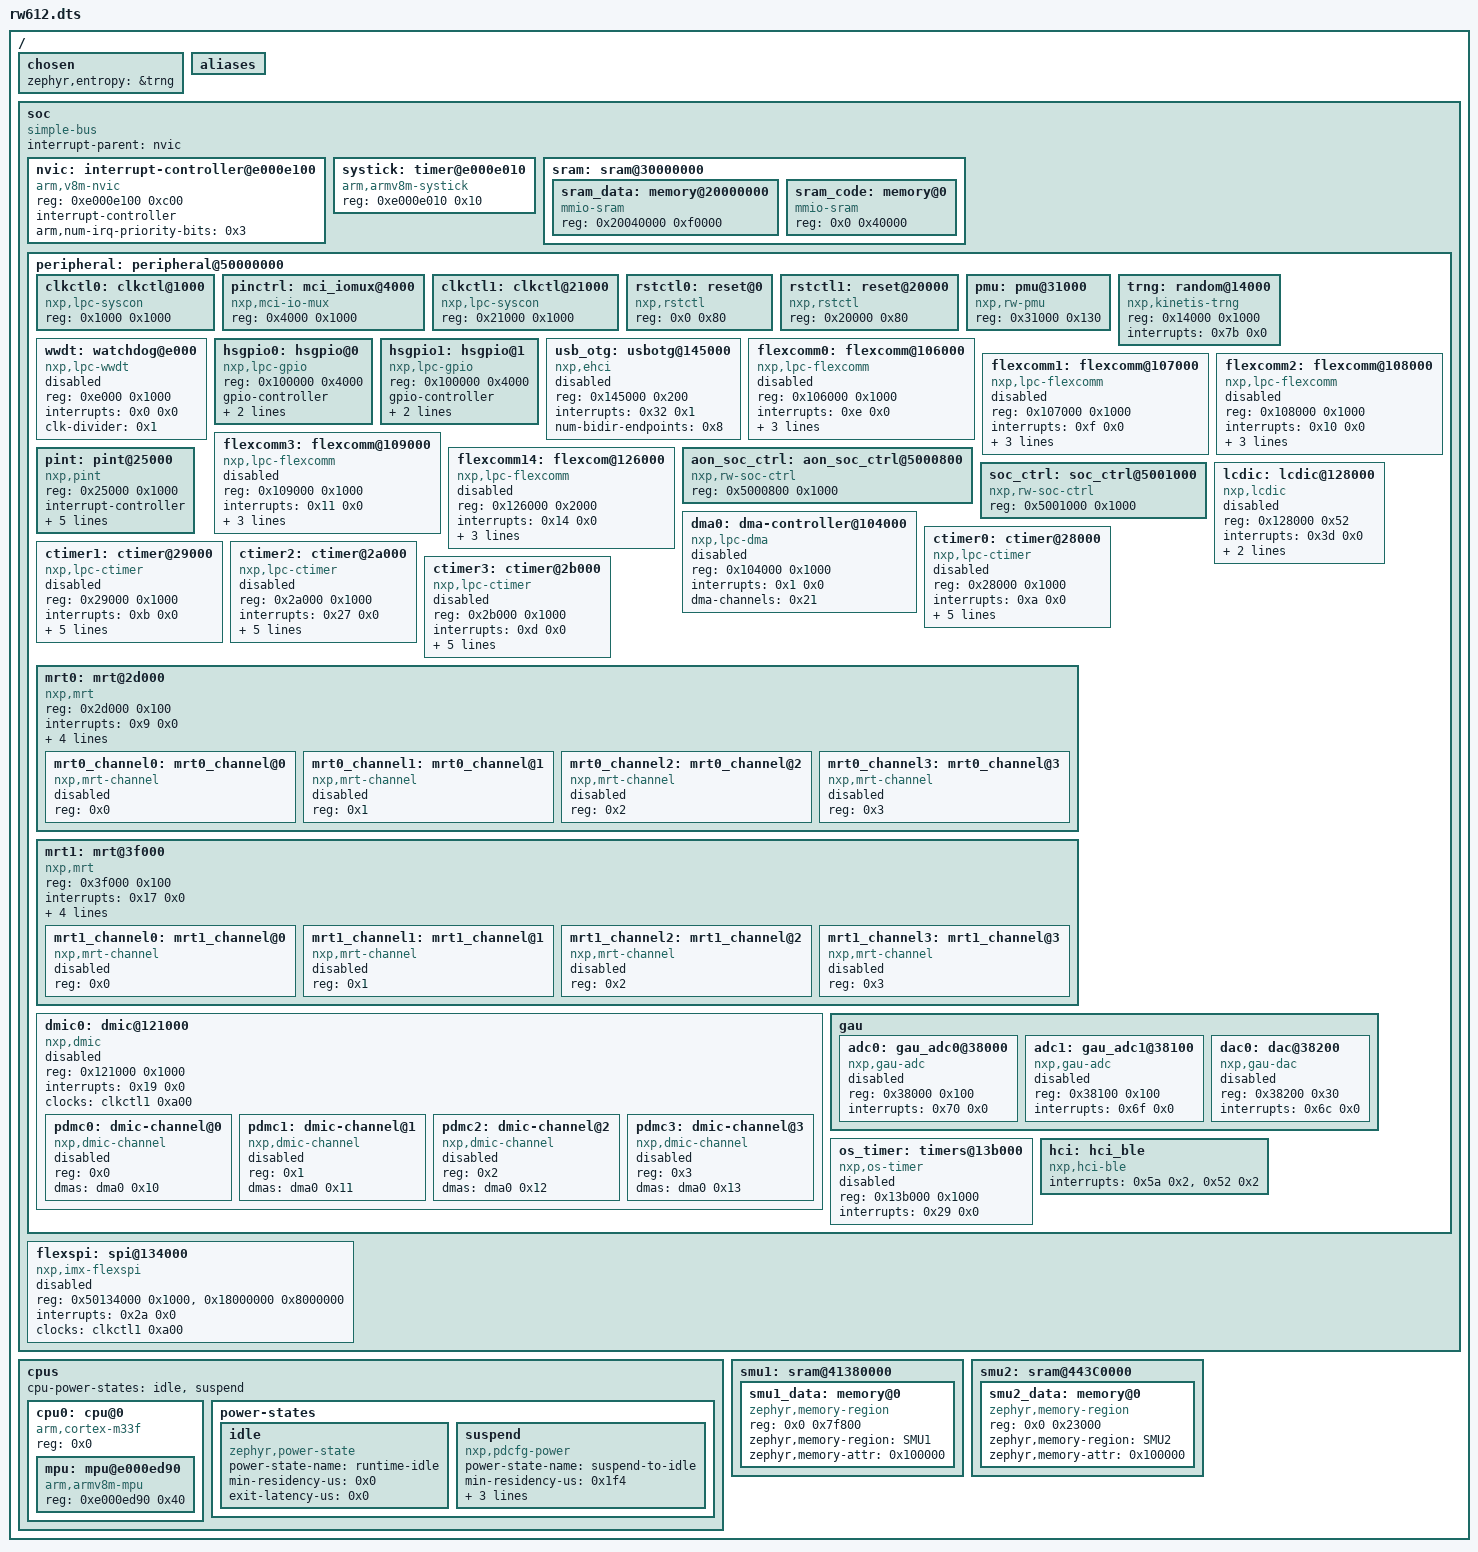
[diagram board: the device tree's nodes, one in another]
/dts-v1/;

/ {
	#address-cells = < 0x1 >;
	#size-cells = < 0x1 >;
	chosen {
		zephyr,entropy = &trng;
	};
	aliases {
	};
	soc {
		#address-cells = < 0x1 >;
		#size-cells = < 0x1 >;
		compatible = "simple-bus";
		interrupt-parent = < &nvic >;
		ranges;
		nvic: interrupt-controller@e000e100 {
			#address-cells = < 0x1 >;
			compatible = "arm,v8m-nvic";
			reg = < 0xe000e100 0xc00 >;
			interrupt-controller;
			#interrupt-cells = < 0x2 >;
			arm,num-irq-priority-bits = < 0x3 >;
			phandle = < 0x1 >;
		};
		systick: timer@e000e010 {
			compatible = "arm,armv8m-systick";
			reg = < 0xe000e010 0x10 >;
		};
		sram: sram@30000000 {
			ranges = < 0x20000000 0x30000000 0x130000 0x0 0x10000000 0x130000 >;
			#address-cells = < 0x1 >;
			#size-cells = < 0x1 >;
			sram_data: memory@20000000 {
				compatible = "mmio-sram";
				reg = < 0x20040000 0xf0000 >;
			};
			sram_code: memory@0 {
				compatible = "mmio-sram";
				reg = < 0x0 0x40000 >;
			};
		};
		peripheral: peripheral@50000000 {
			ranges = < 0x0 0x50000000 0x10000000 >;
			#address-cells = < 0x1 >;
			#size-cells = < 0x1 >;
			clkctl0: clkctl@1000 {
				compatible = "nxp,lpc-syscon";
				reg = < 0x1000 0x1000 >;
				#clock-cells = < 0x1 >;
			};
			pinctrl: mci_iomux@4000 {
				compatible = "nxp,mci-io-mux";
				reg = < 0x4000 0x1000 >;
				status = "okay";
			};
			clkctl1: clkctl@21000 {
				compatible = "nxp,lpc-syscon";
				reg = < 0x21000 0x1000 >;
				#clock-cells = < 0x1 >;
				phandle = < 0x2 >;
			};
			rstctl0: reset@0 {
				compatible = "nxp,rstctl";
				reg = < 0x0 0x80 >;
				#reset-cells = < 0x1 >;
				phandle = < 0x5 >;
			};
			rstctl1: reset@20000 {
				compatible = "nxp,rstctl";
				reg = < 0x20000 0x80 >;
				#reset-cells = < 0x1 >;
				phandle = < 0x3 >;
			};
			pmu: pmu@31000 {
				reg = < 0x31000 0x130 >;
				compatible = "nxp,rw-pmu";
			};
			trng: random@14000 {
				compatible = "nxp,kinetis-trng";
				reg = < 0x14000 0x1000 >;
				status = "okay";
				interrupts = < 0x7b 0x0 >;
			};
			wwdt: watchdog@e000 {
				compatible = "nxp,lpc-wwdt";
				reg = < 0xe000 0x1000 >;
				interrupts = < 0x0 0x0 >;
				status = "disabled";
				clk-divider = < 0x1 >;
			};
			hsgpio0: hsgpio@0 {
				compatible = "nxp,lpc-gpio";
				reg = < 0x100000 0x4000 >;
				gpio-controller;
				#gpio-cells = < 0x2 >;
				port = < 0x0 >;
				int-source = "pint";
			};
			hsgpio1: hsgpio@1 {
				compatible = "nxp,lpc-gpio";
				reg = < 0x100000 0x4000 >;
				gpio-controller;
				#gpio-cells = < 0x2 >;
				port = < 0x1 >;
				int-source = "pint";
			};
			usb_otg: usbotg@145000 {
				compatible = "nxp,ehci";
				reg = < 0x145000 0x200 >;
				interrupts = < 0x32 0x1 >;
				interrupt-names = "usb_otg";
				num-bidir-endpoints = < 0x8 >;
				status = "disabled";
			};
			flexcomm0: flexcomm@106000 {
				compatible = "nxp,lpc-flexcomm";
				reg = < 0x106000 0x1000 >;
				interrupts = < 0xe 0x0 >;
				clocks = < &clkctl1 0x100 >;
				resets = < &rstctl1 0x8 >;
				dmas = < &dma0 0x0 >, < &dma0 0x1 >;
				dma-names = "rx", "tx";
				status = "disabled";
			};
			flexcomm1: flexcomm@107000 {
				compatible = "nxp,lpc-flexcomm";
				reg = < 0x107000 0x1000 >;
				interrupts = < 0xf 0x0 >;
				clocks = < &clkctl1 0x101 >;
				resets = < &rstctl1 0x9 >;
				dmas = < &dma0 0x2 >, < &dma0 0x3 >;
				dma-names = "rx", "tx";
				status = "disabled";
			};
			flexcomm2: flexcomm@108000 {
				compatible = "nxp,lpc-flexcomm";
				reg = < 0x108000 0x1000 >;
				interrupts = < 0x10 0x0 >;
				clocks = < &clkctl1 0x102 >;
				resets = < &rstctl1 0xa >;
				dmas = < &dma0 0x4 >, < &dma0 0x5 >;
				dma-names = "rx", "tx";
				status = "disabled";
			};
			flexcomm3: flexcomm@109000 {
				compatible = "nxp,lpc-flexcomm";
				reg = < 0x109000 0x1000 >;
				interrupts = < 0x11 0x0 >;
				clocks = < &clkctl1 0x103 >;
				resets = < &rstctl1 0xb >;
				dmas = < &dma0 0x6 >, < &dma0 0x7 >;
				dma-names = "rx", "tx";
				status = "disabled";
			};
			flexcomm14: flexcom@126000 {
				compatible = "nxp,lpc-flexcomm";
				reg = < 0x126000 0x2000 >;
				interrupts = < 0x14 0x0 >;
				clocks = < &clkctl1 0x10e >;
				resets = < &rstctl1 0x16 >;
				dmas = < &dma0 0x1a >, < &dma0 0x1b >;
				dma-names = "rx", "tx";
				status = "disabled";
			};
			aon_soc_ctrl: aon_soc_ctrl@5000800 {
				compatible = "nxp,rw-soc-ctrl";
				reg = < 0x5000800 0x1000 >;
				status = "okay";
			};
			soc_ctrl: soc_ctrl@5001000 {
				compatible = "nxp,rw-soc-ctrl";
				reg = < 0x5001000 0x1000 >;
				status = "okay";
			};
			pint: pint@25000 {
				compatible = "nxp,pint";
				reg = < 0x25000 0x1000 >;
				interrupt-controller;
				#interrupt-cells = < 0x1 >;
				#address-cells = < 0x0 >;
				interrupts = < 0x4 0x2 >, < 0x5 0x2 >, < 0x6 0x2 >, < 0x7 0x2 >, < 0x23 0x2 >, < 0x24 0x2 >, < 0x25 0x2 >, < 0x26 0x2 >;
				num-lines = < 0x8 >;
				num-inputs = < 0x40 >;
			};
			dma0: dma-controller@104000 {
				compatible = "nxp,lpc-dma";
				reg = < 0x104000 0x1000 >;
				interrupts = < 0x1 0x0 >;
				status = "disabled";
				#dma-cells = < 0x1 >;
				dma-channels = < 0x21 >;
				phandle = < 0x4 >;
			};
			lcdic: lcdic@128000 {
				compatible = "nxp,lcdic";
				reg = < 0x128000 0x52 >;
				interrupts = < 0x3d 0x0 >;
				status = "disabled";
				#address-cells = < 0x1 >;
				#size-cells = < 0x0 >;
				clocks = < &clkctl1 0xe00 >;
				dmas = < &dma0 0x0 >;
			};
			ctimer0: ctimer@28000 {
				compatible = "nxp,lpc-ctimer";
				reg = < 0x28000 0x1000 >;
				interrupts = < 0xa 0x0 >;
				status = "disabled";
				clk-source = < 0x1 >;
				clocks = < &clkctl1 0x0 >;
				mode = < 0x0 >;
				input = < 0x0 >;
				prescale = < 0x0 >;
			};
			ctimer1: ctimer@29000 {
				compatible = "nxp,lpc-ctimer";
				reg = < 0x29000 0x1000 >;
				interrupts = < 0xb 0x0 >;
				status = "disabled";
				clk-source = < 0x1 >;
				clocks = < &clkctl1 0x1 >;
				mode = < 0x0 >;
				input = < 0x0 >;
				prescale = < 0x0 >;
			};
			ctimer2: ctimer@2a000 {
				compatible = "nxp,lpc-ctimer";
				reg = < 0x2a000 0x1000 >;
				interrupts = < 0x27 0x0 >;
				status = "disabled";
				clk-source = < 0x1 >;
				clocks = < &clkctl1 0x2 >;
				mode = < 0x0 >;
				input = < 0x0 >;
				prescale = < 0x0 >;
			};
			ctimer3: ctimer@2b000 {
				compatible = "nxp,lpc-ctimer";
				reg = < 0x2b000 0x1000 >;
				interrupts = < 0xd 0x0 >;
				status = "disabled";
				clk-source = < 0x1 >;
				clocks = < &clkctl1 0x3 >;
				mode = < 0x0 >;
				input = < 0x0 >;
				prescale = < 0x0 >;
			};
			mrt0: mrt@2d000 {
				compatible = "nxp,mrt";
				reg = < 0x2d000 0x100 >;
				interrupts = < 0x9 0x0 >;
				num-channels = < 0x4 >;
				num-bits = < 0x18 >;
				clocks = < &clkctl1 0xb00 >;
				resets = < &rstctl1 0x20008 >;
				#address-cells = < 0x1 >;
				#size-cells = < 0x0 >;
				mrt0_channel0: mrt0_channel@0 {
					compatible = "nxp,mrt-channel";
					reg = < 0x0 >;
					status = "disabled";
				};
				mrt0_channel1: mrt0_channel@1 {
					compatible = "nxp,mrt-channel";
					reg = < 0x1 >;
					status = "disabled";
				};
				mrt0_channel2: mrt0_channel@2 {
					compatible = "nxp,mrt-channel";
					reg = < 0x2 >;
					status = "disabled";
				};
				mrt0_channel3: mrt0_channel@3 {
					compatible = "nxp,mrt-channel";
					reg = < 0x3 >;
					status = "disabled";
				};
			};
			mrt1: mrt@3f000 {
				compatible = "nxp,mrt";
				reg = < 0x3f000 0x100 >;
				interrupts = < 0x17 0x0 >;
				num-channels = < 0x4 >;
				num-bits = < 0x18 >;
				clocks = < &clkctl1 0xb01 >;
				resets = < &rstctl0 0x2001a >;
				#address-cells = < 0x1 >;
				#size-cells = < 0x0 >;
				mrt1_channel0: mrt1_channel@0 {
					compatible = "nxp,mrt-channel";
					reg = < 0x0 >;
					status = "disabled";
				};
				mrt1_channel1: mrt1_channel@1 {
					compatible = "nxp,mrt-channel";
					reg = < 0x1 >;
					status = "disabled";
				};
				mrt1_channel2: mrt1_channel@2 {
					compatible = "nxp,mrt-channel";
					reg = < 0x2 >;
					status = "disabled";
				};
				mrt1_channel3: mrt1_channel@3 {
					compatible = "nxp,mrt-channel";
					reg = < 0x3 >;
					status = "disabled";
				};
			};
			dmic0: dmic@121000 {
				#address-cells = < 0x1 >;
				#size-cells = < 0x0 >;
				compatible = "nxp,dmic";
				reg = < 0x121000 0x1000 >;
				interrupts = < 0x19 0x0 >;
				status = "disabled";
				clocks = < &clkctl1 0xa00 >;
				pdmc0: dmic-channel@0 {
					reg = < 0x0 >;
					compatible = "nxp,dmic-channel";
					dmas = < &dma0 0x10 >;
					status = "disabled";
				};
				pdmc1: dmic-channel@1 {
					reg = < 0x1 >;
					compatible = "nxp,dmic-channel";
					dmas = < &dma0 0x11 >;
					status = "disabled";
				};
				pdmc2: dmic-channel@2 {
					reg = < 0x2 >;
					compatible = "nxp,dmic-channel";
					dmas = < &dma0 0x12 >;
					status = "disabled";
				};
				pdmc3: dmic-channel@3 {
					reg = < 0x3 >;
					compatible = "nxp,dmic-channel";
					dmas = < &dma0 0x13 >;
					status = "disabled";
				};
			};
			gau {
				ranges;
				#address-cells = < 0x1 >;
				#size-cells = < 0x1 >;
				adc0: gau_adc0@38000 {
					compatible = "nxp,gau-adc";
					reg = < 0x38000 0x100 >;
					interrupts = < 0x70 0x0 >;
					status = "disabled";
					#io-channel-cells = < 0x1 >;
				};
				adc1: gau_adc1@38100 {
					compatible = "nxp,gau-adc";
					reg = < 0x38100 0x100 >;
					interrupts = < 0x6f 0x0 >;
					status = "disabled";
					#io-channel-cells = < 0x1 >;
				};
				dac0: dac@38200 {
					compatible = "nxp,gau-dac";
					reg = < 0x38200 0x30 >;
					interrupts = < 0x6c 0x0 >;
					status = "disabled";
					#io-channel-cells = < 0x0 >;
				};
			};
			os_timer: timers@13b000 {
				compatible = "nxp,os-timer";
				reg = < 0x13b000 0x1000 >;
				interrupts = < 0x29 0x0 >;
				status = "disabled";
			};
			hci: hci_ble {
				compatible = "nxp,hci-ble";
				interrupts = < 0x5a 0x2 >, < 0x52 0x2 >;
				interrupt-names = "hci_int", "wakeup_int";
			};
		};
		flexspi: spi@134000 {
			reg = < 0x50134000 0x1000 >, < 0x18000000 0x8000000 >;
			compatible = "nxp,imx-flexspi";
			status = "disabled";
			interrupts = < 0x2a 0x0 >;
			#address-cells = < 0x1 >;
			#size-cells = < 0x0 >;
			clocks = < &clkctl1 0xa00 >;
		};
	};
	cpus {
		#address-cells = < 0x1 >;
		#size-cells = < 0x0 >;
		cpu-power-states = < &idle &suspend >;
		cpu0: cpu@0 {
			compatible = "arm,cortex-m33f";
			reg = < 0x0 >;
			#address-cells = < 0x1 >;
			#size-cells = < 0x1 >;
			mpu: mpu@e000ed90 {
				compatible = "arm,armv8m-mpu";
				reg = < 0xe000ed90 0x40 >;
			};
		};
		power-states {
			idle: idle {
				compatible = "zephyr,power-state";
				power-state-name = "runtime-idle";
				min-residency-us = < 0x0 >;
				exit-latency-us = < 0x0 >;
				phandle = < 0x6 >;
			};
			suspend: suspend {
				compatible = "nxp,pdcfg-power", "zephyr,power-state";
				power-state-name = "suspend-to-idle";
				min-residency-us = < 0x1f4 >;
				exit-latency-us = < 0x78 >;
				deep-sleep-config = < 0x180000 >, < 0x0 >, < 0x4 >, < 0x100 >, < 0x0 >;
				phandle = < 0x7 >;
			};
		};
	};
	smu1: sram@41380000 {
		ranges = < 0x0 0x41380000 0x7f800 >;
		#address-cells = < 0x1 >;
		#size-cells = < 0x1 >;
		smu1_data: memory@0 {
			compatible = "zephyr,memory-region", "mmio-sram";
			reg = < 0x0 0x7f800 >;
			zephyr,memory-region = "SMU1";
			zephyr,memory-attr = < 0x100000 >;
		};
	};
	smu2: sram@443C0000 {
		ranges = < 0x0 0x443c0000 0x23000 >;
		#address-cells = < 0x1 >;
		#size-cells = < 0x1 >;
		smu2_data: memory@0 {
			compatible = "zephyr,memory-region", "mmio-sram";
			reg = < 0x0 0x23000 >;
			zephyr,memory-region = "SMU2";
			zephyr,memory-attr = < 0x100000 >;
		};
	};
};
